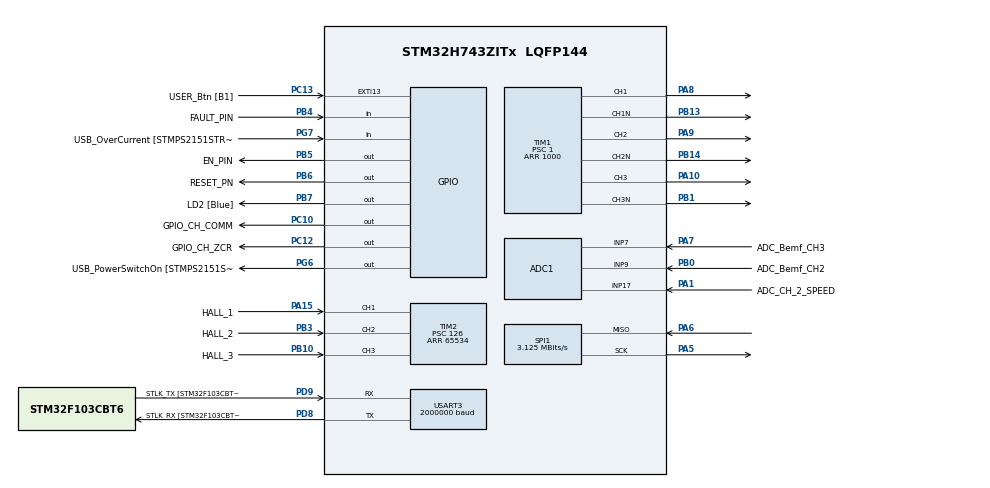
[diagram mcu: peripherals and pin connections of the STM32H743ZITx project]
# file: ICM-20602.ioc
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ADC1.Channel-0\#ChannelRegularConversion=ADC_CHANNEL_9
ADC1.NbrOfConversionFlag=1
ADC1.OffsetNumber-0\#ChannelRegularConversion=ADC_OFFSET_NONE
ADC1.Rank-0\#ChannelRegularConversion=1
ADC1.SamplingTime-0\#ChannelRegularConversion=ADC_SAMPLETIME_1CYCLE_5
ADC1.master=1
CORTEX_M7.CPU_ICache=Enabled
Dma.Request0=SPI1_RX
Dma.SPI1_RX.0.Direction=DMA_PERIPH_TO_MEMORY
Dma.SPI1_RX.0.EventEnable=DISABLE
Dma.SPI1_RX.0.FIFOMode=DMA_FIFOMODE_DISABLE
Dma.SPI1_RX.0.Instance=DMA1_Stream0
Dma.SPI1_RX.0.MemDataAlignment=DMA_MDATAALIGN_WORD
Dma.SPI1_RX.0.MemInc=DMA_MINC_ENABLE
Dma.SPI1_RX.0.Mode=DMA_CIRCULAR
Dma.SPI1_RX.0.PeriphDataAlignment=DMA_PDATAALIGN_WORD
Dma.SPI1_RX.0.PeriphInc=DMA_PINC_DISABLE
Dma.SPI1_RX.0.Polarity=HAL_DMAMUX_REQ_GEN_RISING
Dma.SPI1_RX.0.Priority=DMA_PRIORITY_VERY_HIGH
Dma.SPI1_RX.0.RequestNumber=1
Dma.SPI1_RX.0.SignalID=NONE
Dma.SPI1_RX.0.SyncEnable=DISABLE
Dma.SPI1_RX.0.SyncPolarity=HAL_DMAMUX_SYNC_NO_EVENT
Dma.SPI1_RX.0.SyncRequestNumber=1
Dma.SPI1_RX.0.SyncSignalID=NONE
Mcu.Family=STM32H7
Mcu.Name=STM32H743ZITx
Mcu.Package=LQFP144
NVIC.DMA1_Stream0_IRQn=true\:0\:0\:false\:false\:true\:false\:true
NVIC.EXTI15_10_IRQn=true\:0\:0\:false\:false\:true\:true\:true
NVIC.PriorityGroup=NVIC_PRIORITYGROUP_4
NVIC.SPI1_IRQn=true\:0\:0\:false\:false\:true\:false\:true
NVIC.TIM1_BRK_IRQn=true\:0\:0\:false\:false\:true\:true\:true
NVIC.TIM1_TRG_COM_IRQn=true\:0\:0\:false\:false\:true\:true\:true
NVIC.TIM2_IRQn=true\:0\:0\:false\:false\:true\:true\:true
NVIC.TIM6_DAC_IRQn=true\:0\:0\:false\:false\:true\:true\:true
PA0.GPIO_Label=ADC_CH_1_CURRENT
PA0.Signal=ADC1_INP16
PA1.GPIO_Label=ADC_CH_2_SPEED
PA1.Mode=IN17-Single-Ended
PA1.Signal=ADC1_INP17
PA10.GPIO_Speed=GPIO_SPEED_FREQ_VERY_HIGH
PA10.Signal=S_TIM1_CH3
PA13\ (JTMS/SWDIO).Mode=Serial_Wire
PA13\ (JTMS/SWDIO).Signal=DEBUG_JTMS-SWDIO
PA14\ (JTCK/SWCLK).Mode=Serial_Wire
PA14\ (JTCK/SWCLK).Signal=DEBUG_JTCK-SWCLK
PA15\ (JTDI).GPIO_Label=HALL_1
PA15\ (JTDI).GPIO_Speed=GPIO_SPEED_FREQ_VERY_HIGH
PA15\ (JTDI).Signal=S_TIM2_CH1
PA5.GPIO_PuPd=GPIO_NOPULL
PA5.GPIO_Speed=GPIO_SPEED_FREQ_VERY_HIGH
PA5.Mode=RX_Only_Simplex_Unidirect_Master
PA5.Signal=SPI1_SCK
PA6.GPIO_PuPd=GPIO_NOPULL
PA6.GPIO_Speed=GPIO_SPEED_FREQ_VERY_HIGH
PA6.Mode=RX_Only_Simplex_Unidirect_Master
PA6.Signal=SPI1_MISO
PA7.GPIO_Label=ADC_Bemf_CH3
PA7.Signal=ADCx_INP7
PA8.GPIO_Speed=GPIO_SPEED_FREQ_VERY_HIGH
PA8.Signal=S_TIM1_CH1
PA9.GPIO_Speed=GPIO_SPEED_FREQ_VERY_HIGH
PA9.Signal=S_TIM1_CH2
PB0.GPIO_Label=ADC_Bemf_CH2
PB0.Signal=ADCx_INP9
PB1.GPIO_Speed=GPIO_SPEED_FREQ_VERY_HIGH
PB1.Mode=Output Compare3 CH3 CH3N
PB1.Signal=TIM1_CH3N
PB10.GPIO_Label=HALL_3
PB10.GPIO_Speed=GPIO_SPEED_FREQ_VERY_HIGH
PB10.Signal=S_TIM2_CH3
PB13.GPIO_Speed=GPIO_SPEED_FREQ_VERY_HIGH
PB13.Mode=Output Compare1 CH1 CH1N
PB13.Signal=TIM1_CH1N
PB14.GPIO_Speed=GPIO_SPEED_FREQ_VERY_HIGH
PB14.Mode=Output Compare2 CH2 CH2N
PB14.Signal=TIM1_CH2N
PB3\ (JTDO/TRACESWO).GPIO_Label=HALL_2
PB3\ (JTDO/TRACESWO).GPIO_Speed=GPIO_SPEED_FREQ_VERY_HIGH
PB3\ (JTDO/TRACESWO).Signal=S_TIM2_CH2
PB4\ (NJTRST).GPIO_Label=FAULT_PIN
PB4\ (NJTRST).Signal=GPIO_Input
PB5.GPIO_Label=EN_PIN
PB5.Signal=GPIO_Output
PB6.GPIO_Label=RESET_PN
PB6.Signal=GPIO_Output
PB7.GPIO_Label=LD2 [Blue]
PB7.Signal=GPIO_Output
PC10.GPIO_Label=GPIO_CH_COMM
PC10.Signal=GPIO_Output
PC12.GPIO_Label=GPIO_CH_ZCR
PC12.Signal=GPIO_Output
PC13.GPIO_Label=USER_Btn [B1]
PC13.Signal=GPXTI13
PC14-OSC32_IN\ (OSC32_IN).Signal=RCC_OSC32_IN
PC15-OSC32_OUT\ (OSC32_OUT).Signal=RCC_OSC32_OUT
PC3_C.GPIO_Label=ADC_Bemf_CH1ADC_Bemf_CH1
PC3_C.Signal=ADC3_INP1
PD8.GPIO_Label=STLK_RX [STM32F103CBT6_PA3]
PD8.Mode=Asynchronous
PD8.Signal=USART3_TX
PD9.GPIO_Label=STLK_TX [STM32F103CBT6_PA2]
PD9.Mode=Asynchronous
PD9.Signal=USART3_RX
PG11.GPIO_Label=RMII_TX_EN
PG11.Signal=ETH_TX_EN
PG13.GPIO_Label=RMII_TXD0
PG13.Signal=ETH_TXD0
PG6.GPIO_Label=USB_PowerSwitchOn [STMPS2151STR_EN]
PG6.Signal=GPIO_Output
PG7.GPIO_Label=USB_OverCurrent [STMPS2151STR_FAULT]
PG7.Signal=GPIO_Input
PH0-OSC_IN\ (PH0).GPIO_Label=MCO
PH0-OSC_IN\ (PH0).Signal=RCC_OSC_IN
ProjectManager.HeapSize=0x200
ProjectManager.StackSize=0x400
ProjectManager.TargetToolchain=SW4STM32
RCC.48MHZClocksFreq_Value=24000000
RCC.ADCFreq_Value=160000000
RCC.AHBFreq_Value=216000000
RCC.APB1CLKDivider=RCC_HCLK_DIV4
RCC.APB1Freq_Value=100000000
RCC.APB1TimFreq_Value=108000000
RCC.APB2CLKDivider=RCC_HCLK_DIV2
RCC.APB2Freq_Value=100000000
RCC.APB2TimFreq_Value=216000000
RCC.APB3Freq_Value=100000000
RCC.APB4Freq_Value=100000000
RCC.CortexFreq_Value=400000000
RCC.D1PPRE=RCC_APB3_DIV2
RCC.D2PPRE1=RCC_APB1_DIV2
RCC.D2PPRE2=RCC_APB2_DIV2
RCC.D3PPRE=RCC_APB4_DIV2
RCC.DIVM1=4
RCC.DIVM2=4
RCC.DIVN1=50
RCC.DIVN2=10
RCC.DIVP2=1
RCC.HCLKFreq_Value=200000000
RCC.HPRE=RCC_HCLK_DIV2
RCC.HSE_VALUE=8000000
RCC.HSI_VALUE=64000000
RCC.PLLM=25
RCC.PLLMUL=RCC_PLL_MUL9
RCC.PLLN=432
RCC.PLLQ=9
RCC.PRESCALERUSB=RCC_USBCLKSOURCE_PLL_DIV1_5
RCC.PWR_Regulator_Voltage_Scale=PWR_REGULATOR_VOLTAGE_SCALE0
RCC.SYSCLKFreq_VALUE=400000000
RCC.SYSCLKSource=RCC_SYSCLKSOURCE_PLLCLK
RCC.SYSCLKSourceVirtual=RCC_SYSCLKSOURCE_PLLCLK
RCC.USBCLockSelection=RCC_USBCLKSOURCE_HSI48
RCC.USBFreq_Value=48000000
RCC.VCOOutputFreq_Value=432000000
SH.ADCx_INP7.0=ADC1_INP7,IN7-Single-Ended
SH.ADCx_INP9.0=ADC1_INP9,IN9-Single-Ended
SH.S_TIM1_CH1.0=TIM1_CH1,Output Compare1 CH1 CH1N
SH.S_TIM1_CH2.0=TIM1_CH2,Output Compare2 CH2 CH2N
SH.S_TIM1_CH3.0=TIM1_CH3,Output Compare3 CH3 CH3N
SH.S_TIM2_CH1.0=TIM2_CH1,Xored_Inputs_Hall_Sensor_Interface
SH.S_TIM2_CH2.0=TIM2_CH2,Xored_Inputs_Hall_Sensor_Interface
SH.S_TIM2_CH3.0=TIM2_CH3,Xored_Inputs_Hall_Sensor_Interface
SPI1.BaudRatePrescaler=SPI_BAUDRATEPRESCALER_128
SPI1.CLKPolarity=SPI_POLARITY_HIGH
SPI1.CRCCalculation=SPI_CRCCALCULATION_DISABLE
SPI1.CalculateBaudRate=3.125 MBits/s
SPI1.DataSize=SPI_DATASIZE_25BIT
SPI1.Direction=SPI_DIRECTION_2LINES_RXONLY
SPI1.MasterKeepIOState=SPI_MASTER_KEEP_IO_STATE_DISABLE
SPI1.MasterReceiverAutoSusp=SPI_MASTER_RX_AUTOSUSP_DISABLE
SPI1.Mode=SPI_MODE_MASTER
SPI1.NSSPMode=SPI_NSS_PULSE_DISABLE
SPI1.RxCRCInitializationPattern=SPI_CRC_INITIALIZATION_ALL_ZERO_PATTERN
SPI1.TxCRCInitializationPattern=SPI_CRC_INITIALIZATION_ALL_ZERO_PATTERN
SPI1.VirtualType=VM_MASTER
TIM1.AutomaticOutput=TIM_AUTOMATICOUTPUT_ENABLE
TIM1.BreakState=TIM_BREAK_DISABLE
TIM1.Channel-Output\ Compare1\ CH1\ CH1N=TIM_CHANNEL_1
TIM1.Channel-Output\ Compare2\ CH2\ CH2N=TIM_CHANNEL_2
TIM1.Channel-Output\ Compare3\ CH3\ CH3N=TIM_CHANNEL_3
TIM1.DeadTime=18
TIM1.OCIdleState_1=TIM_OCIDLESTATE_SET
TIM1.OCIdleState_2=TIM_OCIDLESTATE_SET
TIM1.OCIdleState_3=TIM_OCIDLESTATE_SET
TIM1.OCNIdleState_1=TIM_OCNIDLESTATE_SET
TIM1.OCNIdleState_2=TIM_OCNIDLESTATE_SET
TIM1.OCNIdleState_3=TIM_OCNIDLESTATE_SET
TIM1.OffStateIDLEMode=TIM_OSSI_ENABLE
TIM1.OffStateRunMode=TIM_OSSR_ENABLE
TIM1.Period=1000
TIM1.Prescaler=1
TIM1.Pulse-Output\ Compare1\ CH1\ CH1N=999
TIM1.Pulse-Output\ Compare2\ CH2\ CH2N=999
TIM1.Pulse-Output\ Compare3\ CH3\ CH3N=999
TIM1.SourceBRKDigInput=TIM_BREAKINPUTSOURCE_DISABLE
TIM2.Commutation_Delay=1
TIM2.IC1Filter=0xF
TIM2.Period=65534
TIM2.Prescaler=126
TIM6.Period=65535
TIM6.Prescaler=65535
USART3.BaudRate=2000000
USART3.VirtualMode-Asynchronous=VM_ASYNC
VP_TIM2_VS_ClockSourceINT.Mode=Internal
VP_TIM6_VS_ClockSourceINT.Mode=Enable_Timer
board=NUCLEO-H743ZI

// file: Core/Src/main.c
/* USER CODE BEGIN Header */
/**
 ******************************************************************************
 * @file           : main.c
 * @brief          : Main program body
 ******************************************************************************
 * @attention
 *
 * <h2><center>&copy; Copyright (c) 2019 STMicroelectronics.
 * All rights reserved.</center></h2>
 *
 * This software component is licensed by ST under BSD 3-Clause license,
 * the "License"; You may not use this file except in compliance with the
 * License. You may obtain a copy of the License at:
 *                        opensource.org/licenses/BSD-3-Clause
 *
 ******************************************************************************
 */
/* USER CODE END Header */

#include "main.h"
#include "adc.h"
#include "dma.h"
#include "spi.h"
#include "tim.h"
#include "usart.h"
#include "gpio.h"

/* USER CODE BEGIN Includes */
#include "stdio.h"

/* USER CODE END Includes */

void SystemClock_Config(void);

int main(void)
{

  /* Enable I-Cache---------------------------------------------------------*/
  SCB_EnableICache();

  /* MCU Configuration--------------------------------------------------------*/

  /* Reset of all peripherals, Initializes the Flash interface and the Systick. */
  HAL_Init();

  /* Configure the system clock */
  SystemClock_Config();

  /* Initialize all configured peripherals */
  MX_GPIO_Init();
  MX_DMA_Init();
  MX_USART3_UART_Init();
  MX_ADC1_Init();
  MX_TIM1_Init();
  MX_TIM2_Init();
  MX_SPI1_Init();
  MX_TIM6_Init();

  /* Infinite loop */
  /* USER CODE BEGIN WHILE */
  while (1)
  {
	printf("HELLO BLDC WORLD \n\r");

    /* USER CODE END WHILE */

  }
}

void SystemClock_Config(void)
{
  RCC_OscInitTypeDef RCC_OscInitStruct = {0};
  RCC_ClkInitTypeDef RCC_ClkInitStruct = {0};
  RCC_PeriphCLKInitTypeDef PeriphClkInitStruct = {0};

  /** Supply configuration update enable
  */
  HAL_PWREx_ConfigSupply(PWR_LDO_SUPPLY);
  /** Configure the main internal regulator output voltage
  */
  __HAL_PWR_VOLTAGESCALING_CONFIG(PWR_REGULATOR_VOLTAGE_SCALE0);

  while(!__HAL_PWR_GET_FLAG(PWR_FLAG_VOSRDY)) {}
  /** Macro to configure the PLL clock source
  */
  __HAL_RCC_PLL_PLLSOURCE_CONFIG(RCC_PLLSOURCE_HSI);
  /** Initializes the CPU, AHB and APB busses clocks
  */
  RCC_OscInitStruct.OscillatorType = RCC_OSCILLATORTYPE_HSI;
  RCC_OscInitStruct.HSIState = RCC_HSI_DIV1;
  RCC_OscInitStruct.HSICalibrationValue = RCC_HSICALIBRATION_DEFAULT;
  RCC_OscInitStruct.PLL.PLLState = RCC_PLL_ON;
  RCC_OscInitStruct.PLL.PLLSource = RCC_PLLSOURCE_HSI;
  RCC_OscInitStruct.PLL.PLLM = 4;
  RCC_OscInitStruct.PLL.PLLN = 50;
  RCC_OscInitStruct.PLL.PLLP = 2;
  RCC_OscInitStruct.PLL.PLLQ = 2;
  RCC_OscInitStruct.PLL.PLLR = 2;
  RCC_OscInitStruct.PLL.PLLRGE = RCC_PLL1VCIRANGE_3;
  RCC_OscInitStruct.PLL.PLLVCOSEL = RCC_PLL1VCOWIDE;
  RCC_OscInitStruct.PLL.PLLFRACN = 0;
  if (HAL_RCC_OscConfig(&RCC_OscInitStruct) != HAL_OK)
  {
    Error_Handler();
  }
  /** Initializes the CPU, AHB and APB busses clocks
  */
  RCC_ClkInitStruct.ClockType = RCC_CLOCKTYPE_HCLK|RCC_CLOCKTYPE_SYSCLK
                              |RCC_CLOCKTYPE_PCLK1|RCC_CLOCKTYPE_PCLK2
                              |RCC_CLOCKTYPE_D3PCLK1|RCC_CLOCKTYPE_D1PCLK1;
  RCC_ClkInitStruct.SYSCLKSource = RCC_SYSCLKSOURCE_PLLCLK;
  RCC_ClkInitStruct.SYSCLKDivider = RCC_SYSCLK_DIV1;
  RCC_ClkInitStruct.AHBCLKDivider = RCC_HCLK_DIV2;
  RCC_ClkInitStruct.APB3CLKDivider = RCC_APB3_DIV2;
  RCC_ClkInitStruct.APB1CLKDivider = RCC_APB1_DIV2;
  RCC_ClkInitStruct.APB2CLKDivider = RCC_APB2_DIV2;
  RCC_ClkInitStruct.APB4CLKDivider = RCC_APB4_DIV2;

  if (HAL_RCC_ClockConfig(&RCC_ClkInitStruct, FLASH_LATENCY_2) != HAL_OK)
  {
    Error_Handler();
  }
  PeriphClkInitStruct.PeriphClockSelection = RCC_PERIPHCLK_USART3|RCC_PERIPHCLK_SPI1
                              |RCC_PERIPHCLK_ADC;
  PeriphClkInitStruct.PLL2.PLL2M = 4;
  PeriphClkInitStruct.PLL2.PLL2N = 10;
  PeriphClkInitStruct.PLL2.PLL2P = 1;
  PeriphClkInitStruct.PLL2.PLL2Q = 2;
  PeriphClkInitStruct.PLL2.PLL2R = 2;
  PeriphClkInitStruct.PLL2.PLL2RGE = RCC_PLL2VCIRANGE_3;
  PeriphClkInitStruct.PLL2.PLL2VCOSEL = RCC_PLL2VCOMEDIUM;
  PeriphClkInitStruct.PLL2.PLL2FRACN = 0;
  PeriphClkInitStruct.Spi123ClockSelection = RCC_SPI123CLKSOURCE_PLL;
  PeriphClkInitStruct.Usart234578ClockSelection = RCC_USART234578CLKSOURCE_D2PCLK1;
  PeriphClkInitStruct.AdcClockSelection = RCC_ADCCLKSOURCE_PLL2;
  if (HAL_RCCEx_PeriphCLKConfig(&PeriphClkInitStruct) != HAL_OK)
  {
    Error_Handler();
  }
}

void Error_Handler(void)
{
}

/************************ (C) COPYRIGHT STMicroelectronics *****END OF FILE****/
